VERSION ""

NS_ :

BS_:
BU_:
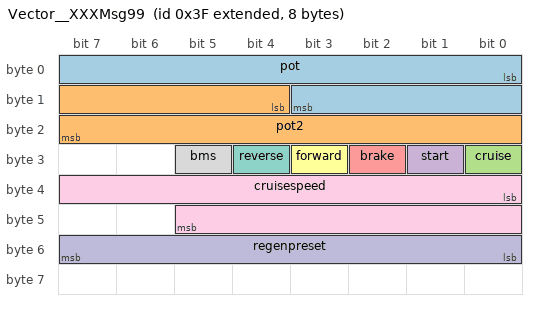
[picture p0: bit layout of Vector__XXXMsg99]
BO_ 2147483711 Vector__XXXMsg99: 8 Vector__XXX
   SG_ pot : 0|12@1+ (1,0) [0|1] "" Vector__XXX
   SG_ pot2 : 12|12@1+ (1,0) [0|1] "" Vector__XXX
   SG_ cruise : 24|1@1+ (1,0) [0|1] "" Vector__XXX
   SG_ start : 25|1@1+ (1,0) [0|1] "" Vector__XXX
   SG_ brake : 26|1@1+ (1,0) [0|1] "" Vector__XXX
   SG_ forward : 27|1@1+ (1,0) [0|1] "" Vector__XXX
   SG_ reverse : 28|1@1+ (1,0) [0|1] "" Vector__XXX
   SG_ bms : 29|1@1+ (1,0) [0|1] "" Vector__XXX
   SG_ cruisespeed : 32|14@1+ (1,0) [0|1] "" Vector__XXX
   SG_ regenpreset : 48|8@1+ (1,0) [0|1] "" Vector__XXX

BA_DEF_ BO_ "GenMsgBackgroundColor" STRING ;
BA_DEF_ BO_ "GenMsgForegroundColor" STRING ;
BA_DEF_ BO_ "filterlabeling" INT 0 0;
BA_DEF_DEF_ "GenMsgBackgroundColor" "#ffffff";
BA_DEF_DEF_ "GenMsgForegroundColor" "#000000";
BA_DEF_DEF_ "filterlabeling" 1;
BA_ "GenMsgBackgroundColor" BO_ 2147483711 "#57e389";
